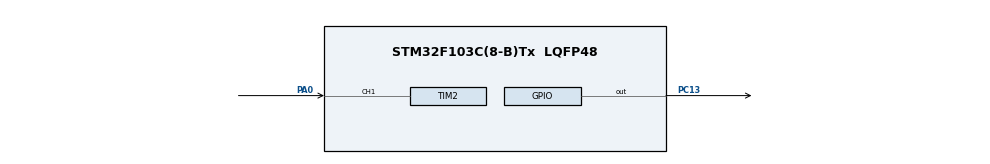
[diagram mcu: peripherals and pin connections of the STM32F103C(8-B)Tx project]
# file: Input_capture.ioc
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Mcu.Family=STM32F1
Mcu.Name=STM32F103C(8-B)Tx
Mcu.Package=LQFP48
NVIC.PriorityGroup=NVIC_PRIORITYGROUP_4
NVIC.TIM2_IRQn=true\:0\:0\:false\:false\:true\:true\:true\:true
PA0-WKUP.Signal=S_TIM2_CH1_ETR
PA13.Mode=Serial_Wire
PA13.Signal=SYS_JTMS-SWDIO
PA14.Mode=Serial_Wire
PA14.Signal=SYS_JTCK-SWCLK
PC13-TAMPER-RTC.Signal=GPIO_Output
ProjectManager.HeapSize=0x200
ProjectManager.StackSize=0x400
ProjectManager.TargetToolchain=MDK-ARM V5
RCC.APB1Freq_Value=8000000
RCC.APB2Freq_Value=8000000
SH.S_TIM2_CH1_ETR.0=TIM2_CH1,Input_Capture1_from_TI1
TIM2.Channel-Input_Capture1_from_TI1=TIM_CHANNEL_1
TIM2.Period=10000-1
TIM2.Prescaler=8-1
VP_TIM2_VS_ClockSourceINT.Mode=Internal
board=custom

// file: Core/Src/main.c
/* USER CODE BEGIN Header */
/**
  ******************************************************************************
  * @file           : main.c
  * @brief          : Main program body
  ******************************************************************************
  * @attention
  *
  * Copyright (c) 2023 STMicroelectronics.
  * All rights reserved.
  *
  * This software is licensed under terms that can be found in the LICENSE file
  * in the root directory of this software component.
  * If no LICENSE file comes with this software, it is provided AS-IS.
  *
  ******************************************************************************
  */
/* USER CODE END Header */
#include "main.h"

TIM_HandleTypeDef htim2;

void SystemClock_Config(void);
static void MX_GPIO_Init(void);
static void MX_TIM2_Init(void);
/* USER CODE BEGIN PFP */
uint32_t current_value=0;
uint32_t code =0;
uint32_t temp_code =0;
uint8_t cmd=0;
uint8_t cmd_resever = 0;
uint8_t bit_count=0;

/* USER CODE END PFP */

/* USER CODE BEGIN 0 */
void NEC_Infra_Trans_Handle(void)
{
	if (HAL_TIM_ReadCapturedValue(&htim2,TIM_CHANNEL_1)>8000) //10=1ms
	{
		temp_code = 0;
		bit_count = 0;
	}
	else if (HAL_TIM_ReadCapturedValue(&htim2,TIM_CHANNEL_1)>1700)
	{
		temp_code |= (1<<(31-bit_count));
		bit_count++;
	}
	else if (HAL_TIM_ReadCapturedValue(&htim2,TIM_CHANNEL_1)>1000)
	{
		temp_code &= ~(1<<(31-bit_count));
		bit_count++;
	}

	if (bit_count==32) {
		cmd_resever=~temp_code;
		cmd=temp_code>>8;
		if (cmd==cmd_resever) {
			code = temp_code;
		}
	}

}
/* USER CODE END 0 */

int main(void)
{

  /* MCU Configuration--------------------------------------------------------*/

  /* Reset of all peripherals, Initializes the Flash interface and the Systick. */
  HAL_Init();

  /* Configure the system clock */
  SystemClock_Config();

  /* Initialize all configured peripherals */
  MX_GPIO_Init();
  MX_TIM2_Init();
  /* USER CODE BEGIN 2 */
	HAL_TIM_IC_Start_IT(&htim2,TIM_CHANNEL_1);
  /* USER CODE END 2 */

  /* Infinite loop */
  while (1)
  {

    /* USER CODE BEGIN 3 */
		NEC_Infra_Trans_Handle();
		current_value = HAL_TIM_ReadCapturedValue(&htim2,TIM_CHANNEL_1);
  }
  /* USER CODE END 3 */
}

void SystemClock_Config(void)
{
  RCC_OscInitTypeDef RCC_OscInitStruct = {0};
  RCC_ClkInitTypeDef RCC_ClkInitStruct = {0};

  /** Initializes the RCC Oscillators according to the specified parameters
  * in the RCC_OscInitTypeDef structure.
  */
  RCC_OscInitStruct.OscillatorType = RCC_OSCILLATORTYPE_HSI;
  RCC_OscInitStruct.HSIState = RCC_HSI_ON;
  RCC_OscInitStruct.HSICalibrationValue = RCC_HSICALIBRATION_DEFAULT;
  RCC_OscInitStruct.PLL.PLLState = RCC_PLL_NONE;
  if (HAL_RCC_OscConfig(&RCC_OscInitStruct) != HAL_OK)
  {
    Error_Handler();
  }

  /** Initializes the CPU, AHB and APB buses clocks
  */
  RCC_ClkInitStruct.ClockType = RCC_CLOCKTYPE_HCLK|RCC_CLOCKTYPE_SYSCLK
                              |RCC_CLOCKTYPE_PCLK1|RCC_CLOCKTYPE_PCLK2;
  RCC_ClkInitStruct.SYSCLKSource = RCC_SYSCLKSOURCE_HSI;
  RCC_ClkInitStruct.AHBCLKDivider = RCC_SYSCLK_DIV1;
  RCC_ClkInitStruct.APB1CLKDivider = RCC_HCLK_DIV1;
  RCC_ClkInitStruct.APB2CLKDivider = RCC_HCLK_DIV1;

  if (HAL_RCC_ClockConfig(&RCC_ClkInitStruct, FLASH_LATENCY_0) != HAL_OK)
  {
    Error_Handler();
  }
}

static void MX_TIM2_Init(void)
{

  TIM_ClockConfigTypeDef sClockSourceConfig = {0};
  TIM_MasterConfigTypeDef sMasterConfig = {0};
  TIM_IC_InitTypeDef sConfigIC = {0};

  htim2.Instance = TIM2;
  htim2.Init.Prescaler = 8-1;
  htim2.Init.CounterMode = TIM_COUNTERMODE_UP;
  htim2.Init.Period = 10000-1;
  htim2.Init.ClockDivision = TIM_CLOCKDIVISION_DIV1;
  htim2.Init.AutoReloadPreload = TIM_AUTORELOAD_PRELOAD_DISABLE;
  if (HAL_TIM_Base_Init(&htim2) != HAL_OK)
  {
    Error_Handler();
  }
  sClockSourceConfig.ClockSource = TIM_CLOCKSOURCE_INTERNAL;
  if (HAL_TIM_ConfigClockSource(&htim2, &sClockSourceConfig) != HAL_OK)
  {
    Error_Handler();
  }
  if (HAL_TIM_IC_Init(&htim2) != HAL_OK)
  {
    Error_Handler();
  }
  sMasterConfig.MasterOutputTrigger = TIM_TRGO_RESET;
  sMasterConfig.MasterSlaveMode = TIM_MASTERSLAVEMODE_DISABLE;
  if (HAL_TIMEx_MasterConfigSynchronization(&htim2, &sMasterConfig) != HAL_OK)
  {
    Error_Handler();
  }
  sConfigIC.ICPolarity = TIM_INPUTCHANNELPOLARITY_RISING;
  sConfigIC.ICSelection = TIM_ICSELECTION_DIRECTTI;
  sConfigIC.ICPrescaler = TIM_ICPSC_DIV1;
  sConfigIC.ICFilter = 0;
  if (HAL_TIM_IC_ConfigChannel(&htim2, &sConfigIC, TIM_CHANNEL_1) != HAL_OK)
  {
    Error_Handler();
  }

}

static void MX_GPIO_Init(void)
{
  GPIO_InitTypeDef GPIO_InitStruct = {0};

  /* GPIO Ports Clock Enable */
  __HAL_RCC_GPIOC_CLK_ENABLE();
  __HAL_RCC_GPIOA_CLK_ENABLE();

  /*Configure GPIO pin Output Level */
  HAL_GPIO_WritePin(GPIOC, GPIO_PIN_13, GPIO_PIN_RESET);

  /*Configure GPIO pin : PC13 */
  GPIO_InitStruct.Pin = GPIO_PIN_13;
  GPIO_InitStruct.Mode = GPIO_MODE_OUTPUT_PP;
  GPIO_InitStruct.Pull = GPIO_NOPULL;
  GPIO_InitStruct.Speed = GPIO_SPEED_FREQ_LOW;
  HAL_GPIO_Init(GPIOC, &GPIO_InitStruct);

}

void Error_Handler(void)
{
  __disable_irq();
  while (1)
  {
  }
}
